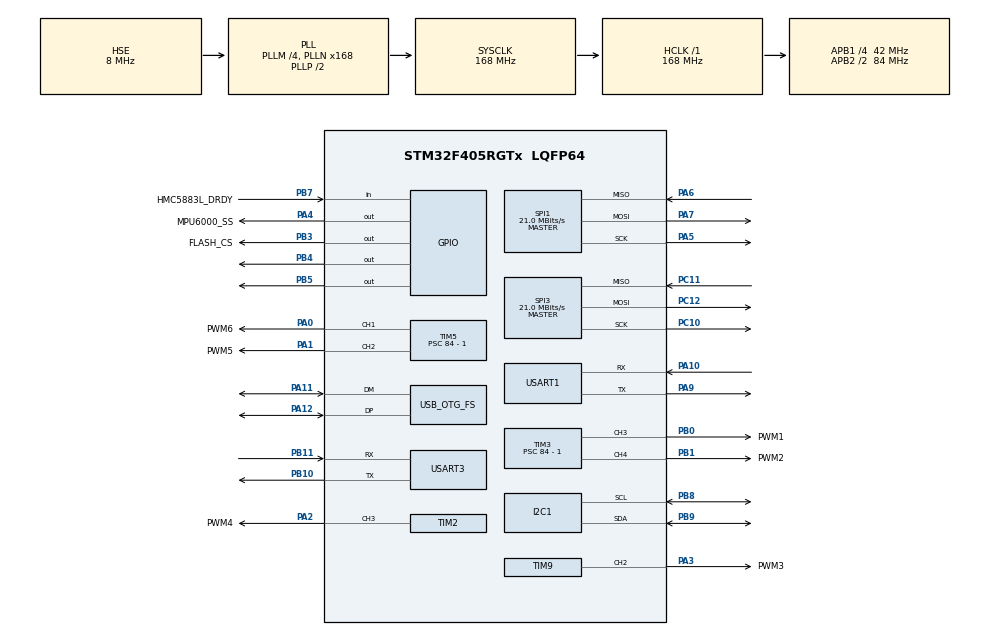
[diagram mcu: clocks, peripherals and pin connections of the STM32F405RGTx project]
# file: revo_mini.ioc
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I2C1.I2C_Mode=I2C_Fast
Mcu.Family=STM32F4
Mcu.Name=STM32F405RGTx
Mcu.Package=LQFP64
NVIC.OTG_FS_IRQn=true\:0\:0\:false\:false\:true\:false
NVIC.PriorityGroup=NVIC_PRIORITYGROUP_4
NVIC.TIM7_IRQn=true\:0\:0\:false\:false\:true\:true
NVIC.USART1_IRQn=true\:0\:0\:false\:false\:true\:true
NVIC.USART3_IRQn=true\:0\:0\:false\:false\:true\:true
PA0-WKUP.GPIO_Label=PWM6
PA0-WKUP.Signal=S_TIM5_CH1
PA1.GPIO_Label=PWM5
PA1.Signal=S_TIM5_CH2
PA10.Mode=Asynchronous
PA10.Signal=USART1_RX
PA11.Mode=Device_Only
PA11.Signal=USB_OTG_FS_DM
PA12.Mode=Device_Only
PA12.Signal=USB_OTG_FS_DP
PA13.Mode=Serial_Wire
PA13.Signal=SYS_JTMS-SWDIO
PA14.Mode=Serial_Wire
PA14.Signal=SYS_JTCK-SWCLK
PA2.GPIO_Label=PWM4
PA2.Signal=S_TIM2_CH3
PA3.GPIO_Label=PWM3
PA3.Signal=S_TIM9_CH2
PA4.GPIO_Label=MPU6000_SS
PA4.GPIO_Speed=GPIO_SPEED_FREQ_HIGH
PA4.PinState=GPIO_PIN_SET
PA4.Signal=GPIO_Output
PA5.Mode=Full_Duplex_Master
PA5.Signal=SPI1_SCK
PA6.Mode=Full_Duplex_Master
PA6.Signal=SPI1_MISO
PA7.Mode=Full_Duplex_Master
PA7.Signal=SPI1_MOSI
PA9.Mode=Asynchronous
PA9.Signal=USART1_TX
PB0.GPIO_Label=PWM1
PB0.Signal=S_TIM3_CH3
PB1.GPIO_Label=PWM2
PB1.Signal=S_TIM3_CH4
PB10.Mode=Asynchronous
PB10.Signal=USART3_TX
PB11.Mode=Asynchronous
PB11.Signal=USART3_RX
PB3.GPIO_Label=FLASH_CS
PB3.GPIO_Speed=GPIO_SPEED_FREQ_HIGH
PB3.PinState=GPIO_PIN_SET
PB3.Signal=GPIO_Output
PB4.Signal=GPIO_Output
PB5.Signal=GPIO_Output
PB7.GPIO_Label=HMC5883L_DRDY
PB7.Signal=GPIO_Input
PB8.Mode=I2C
PB8.Signal=I2C1_SCL
PB9.Mode=I2C
PB9.Signal=I2C1_SDA
PC10.Mode=Full_Duplex_Master
PC10.Signal=SPI3_SCK
PC11.Mode=Full_Duplex_Master
PC11.Signal=SPI3_MISO
PC12.Mode=Full_Duplex_Master
PC12.Signal=SPI3_MOSI
PH0-OSC_IN.Mode=HSE-External-Oscillator
PH0-OSC_IN.Signal=RCC_OSC_IN
PH1-OSC_OUT.Mode=HSE-External-Oscillator
PH1-OSC_OUT.Signal=RCC_OSC_OUT
ProjectManager.HeapSize=0x200
ProjectManager.StackSize=0x400
ProjectManager.TargetToolchain=Makefile
RCC.48MHZClocksFreq_Value=48000000
RCC.AHBFreq_Value=168000000
RCC.APB1CLKDivider=RCC_HCLK_DIV4
RCC.APB1Freq_Value=42000000
RCC.APB1TimFreq_Value=84000000
RCC.APB2CLKDivider=RCC_HCLK_DIV2
RCC.APB2Freq_Value=84000000
RCC.APB2TimFreq_Value=168000000
RCC.CortexFreq_Value=168000000
RCC.HCLKFreq_Value=168000000
RCC.HSE_VALUE=8000000
RCC.HSI_VALUE=16000000
RCC.LSE_VALUE=32768
RCC.PLLM=4
RCC.PLLN=168
RCC.PLLQ=7
RCC.SYSCLKFreq_VALUE=168000000
RCC.SYSCLKSource=RCC_SYSCLKSOURCE_PLLCLK
RCC.VCOOutputFreq_Value=336000000
SH.S_TIM2_CH3.0=TIM2_CH3,PWM Generation3 CH3
SH.S_TIM3_CH3.0=TIM3_CH3,PWM Generation3 CH3
SH.S_TIM3_CH4.0=TIM3_CH4,PWM Generation4 CH4
SH.S_TIM5_CH1.0=TIM5_CH1,PWM Generation1 CH1
SH.S_TIM5_CH2.0=TIM5_CH2,PWM Generation2 CH2
SH.S_TIM9_CH2.0=TIM9_CH2,PWM Generation2 CH2
SPI1.BaudRatePrescaler=SPI_BAUDRATEPRESCALER_4
SPI1.CLKPhase=SPI_PHASE_2EDGE
SPI1.CLKPolarity=SPI_POLARITY_HIGH
SPI1.CalculateBaudRate=21.0 MBits/s
SPI1.Direction=SPI_DIRECTION_2LINES
SPI1.Mode=SPI_MODE_MASTER
SPI1.TIMode=SPI_TIMODE_DISABLE
SPI1.VirtualType=VM_MASTER
SPI3.CLKPhase=SPI_PHASE_2EDGE
SPI3.CLKPolarity=SPI_POLARITY_HIGH
SPI3.CalculateBaudRate=21.0 MBits/s
SPI3.Direction=SPI_DIRECTION_2LINES
SPI3.Mode=SPI_MODE_MASTER
SPI3.VirtualType=VM_MASTER
TIM2.Channel-PWM\ Generation3\ CH3=TIM_CHANNEL_3
TIM2.Period=2083
TIM2.Prescaler=84 - 1
TIM3.Channel-PWM\ Generation3\ CH3=TIM_CHANNEL_3
TIM3.Channel-PWM\ Generation4\ CH4=TIM_CHANNEL_4
TIM3.Period=2083
TIM3.Prescaler=84 - 1
TIM5.Channel-PWM\ Generation1\ CH1=TIM_CHANNEL_1
TIM5.Channel-PWM\ Generation2\ CH2=TIM_CHANNEL_2
TIM5.Period=2083
TIM5.Prescaler=84 - 1
TIM7.Period=0xffff
TIM7.Prescaler=84 - 1
TIM7.TIM_MasterOutputTrigger=TIM_TRGO_RESET
TIM9.Channel-PWM\ Generation2\ CH2=TIM_CHANNEL_2
TIM9.Period=2083
TIM9.Prescaler=168 - 1
USART1.VirtualMode=VM_ASYNC
USART3.VirtualMode=VM_ASYNC
USB_DEVICE.CLASS_NAME_FS=CDC
USB_DEVICE.VirtualMode-CDC_FS=Cdc
USB_DEVICE.VirtualModeFS=Cdc_FS
USB_OTG_FS.VirtualMode=Device_Only
VP_TIM2_VS_ClockSourceINT.Mode=Internal
VP_TIM3_VS_ClockSourceINT.Mode=Internal
VP_TIM5_VS_ClockSourceINT.Mode=Internal
VP_TIM7_VS_ClockSourceINT.Mode=Enable_Timer
VP_TIM9_VS_ClockSourceINT.Mode=Internal
VP_USB_DEVICE_VS_USB_DEVICE_CDC_FS.Mode=CDC_FS
board=custom

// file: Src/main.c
/**
  ******************************************************************************
  * @file           : main.c
  * @brief          : Main program body
  ******************************************************************************
  * This notice applies to any and all portions of this file
  * that are not between comment pairs USER CODE BEGIN and
  * USER CODE END. Other portions of this file, whether
  * inserted by the user or by software development tools
  * are owned by their respective copyright owners.
  *
  * Copyright (c) 2018 STMicroelectronics International N.V.
  * All rights reserved.
  *
  * Redistribution and use in source and binary forms, with or without
  * modification, are permitted, provided that the following conditions are met:
  *
  * 1. Redistribution of source code must retain the above copyright notice,
  *    this list of conditions and the following disclaimer.
  * 2. Redistributions in binary form must reproduce the above copyright notice,
  *    this list of conditions and the following disclaimer in the documentation
  *    and/or other materials provided with the distribution.
  * 3. Neither the name of STMicroelectronics nor the names of other
  *    contributors to this software may be used to endorse or promote products
  *    derived from this software without specific written permission.
  * 4. This software, including modifications and/or derivative works of this
  *    software, must execute solely and exclusively on microcontroller or
  *    microprocessor devices manufactured by or for STMicroelectronics.
  * 5. Redistribution and use of this software other than as permitted under
  *    this license is void and will automatically terminate your rights under
  *    this license.
  *
  * THIS SOFTWARE IS PROVIDED BY STMICROELECTRONICS AND CONTRIBUTORS "AS IS"
  * AND ANY EXPRESS, IMPLIED OR STATUTORY WARRANTIES, INCLUDING, BUT NOT
  * LIMITED TO, THE IMPLIED WARRANTIES OF MERCHANTABILITY, FITNESS FOR A
  * PARTICULAR PURPOSE AND NON-INFRINGEMENT OF THIRD PARTY INTELLECTUAL PROPERTY
  * RIGHTS ARE DISCLAIMED TO THE FULLEST EXTENT PERMITTED BY LAW. IN NO EVENT
  * SHALL STMICROELECTRONICS OR CONTRIBUTORS BE LIABLE FOR ANY DIRECT, INDIRECT,
  * INCIDENTAL, SPECIAL, EXEMPLARY, OR CONSEQUENTIAL DAMAGES (INCLUDING, BUT NOT
  * LIMITED TO, PROCUREMENT OF SUBSTITUTE GOODS OR SERVICES; LOSS OF USE, DATA,
  * OR PROFITS; OR BUSINESS INTERRUPTION) HOWEVER CAUSED AND ON ANY THEORY OF
  * LIABILITY, WHETHER IN CONTRACT, STRICT LIABILITY, OR TORT (INCLUDING
  * NEGLIGENCE OR OTHERWISE) ARISING IN ANY WAY OUT OF THE USE OF THIS SOFTWARE,
  * EVEN IF ADVISED OF THE POSSIBILITY OF SUCH DAMAGE.
  *
  ******************************************************************************
  */
#include "main.h"
#include "stm32f4xx_hal.h"
#include "i2c.h"
#include "spi.h"
#include "tim.h"
#include "usart.h"
#include "usb_device.h"
#include "gpio.h"

/* USER CODE BEGIN Includes */
#include "app.h"
/* USER CODE END Includes */

/* USER CODE BEGIN PV */
/* Private variables ---------------------------------------------------------*/

/* USER CODE END PV */

void SystemClock_Config(void);

/* USER CODE BEGIN PFP */
/* Private function prototypes -----------------------------------------------*/

/* USER CODE END PFP */

int main(void)
{

  /* MCU Configuration----------------------------------------------------------*/

  /* Reset of all peripherals, Initializes the Flash interface and the Systick. */
  HAL_Init();

  /* USER CODE BEGIN Init */
  app_init_f();
  /* USER CODE END Init */

  /* Configure the system clock */
  SystemClock_Config();

  /* Initialize all configured peripherals */
  MX_GPIO_Init();
  MX_TIM2_Init();
  MX_TIM3_Init();
  MX_TIM9_Init();
  MX_TIM5_Init();
  MX_USB_DEVICE_Init();
  MX_SPI1_Init();
  MX_TIM7_Init();
  MX_I2C1_Init();
  MX_SPI3_Init();
  MX_USART1_UART_Init();
  MX_USART3_UART_Init();
  /* USER CODE BEGIN 2 */
  app_init();
  app_start();
  /* USER CODE END 2 */

  /* Infinite loop */
  /* USER CODE BEGIN WHILE */
  app_loop();
  /* USER CODE END WHILE */

}

void SystemClock_Config(void)
{

  RCC_OscInitTypeDef RCC_OscInitStruct;
  RCC_ClkInitTypeDef RCC_ClkInitStruct;

    /**Configure the main internal regulator output voltage
    */
  __HAL_RCC_PWR_CLK_ENABLE();

  __HAL_PWR_VOLTAGESCALING_CONFIG(PWR_REGULATOR_VOLTAGE_SCALE1);

    /**Initializes the CPU, AHB and APB busses clocks
    */
  RCC_OscInitStruct.OscillatorType = RCC_OSCILLATORTYPE_HSE;
  RCC_OscInitStruct.HSEState = RCC_HSE_ON;
  RCC_OscInitStruct.PLL.PLLState = RCC_PLL_ON;
  RCC_OscInitStruct.PLL.PLLSource = RCC_PLLSOURCE_HSE;
  RCC_OscInitStruct.PLL.PLLM = 4;
  RCC_OscInitStruct.PLL.PLLN = 168;
  RCC_OscInitStruct.PLL.PLLP = RCC_PLLP_DIV2;
  RCC_OscInitStruct.PLL.PLLQ = 7;
  if (HAL_RCC_OscConfig(&RCC_OscInitStruct) != HAL_OK)
  {
    _Error_Handler(__FILE__, __LINE__);
  }

    /**Initializes the CPU, AHB and APB busses clocks
    */
  RCC_ClkInitStruct.ClockType = RCC_CLOCKTYPE_HCLK|RCC_CLOCKTYPE_SYSCLK
                              |RCC_CLOCKTYPE_PCLK1|RCC_CLOCKTYPE_PCLK2;
  RCC_ClkInitStruct.SYSCLKSource = RCC_SYSCLKSOURCE_PLLCLK;
  RCC_ClkInitStruct.AHBCLKDivider = RCC_SYSCLK_DIV1;
  RCC_ClkInitStruct.APB1CLKDivider = RCC_HCLK_DIV4;
  RCC_ClkInitStruct.APB2CLKDivider = RCC_HCLK_DIV2;

  if (HAL_RCC_ClockConfig(&RCC_ClkInitStruct, FLASH_LATENCY_5) != HAL_OK)
  {
    _Error_Handler(__FILE__, __LINE__);
  }

    /**Configure the Systick interrupt time
    */
  HAL_SYSTICK_Config(HAL_RCC_GetHCLKFreq()/1000);

    /**Configure the Systick
    */
  HAL_SYSTICK_CLKSourceConfig(SYSTICK_CLKSOURCE_HCLK);

  /* SysTick_IRQn interrupt configuration */
  HAL_NVIC_SetPriority(SysTick_IRQn, 0, 0);
}

void _Error_Handler(char *file, int line)
{
  while(1)
  {
  }
}

/************************ (C) COPYRIGHT STMicroelectronics *****END OF FILE****/
